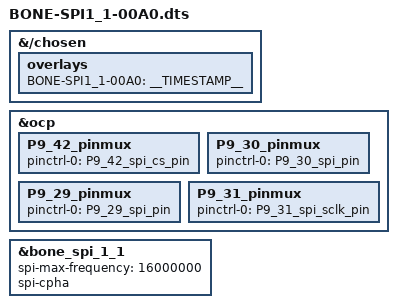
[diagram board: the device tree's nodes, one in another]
/*
 * Copyright (C) 2020 Deepak Khatri <deepaklorkhatri7@gmail.com>
 *
 * Virtual cape for /dev/bone/spi/1.1
 *
 * This program is free software; you can redistribute it and/or modify
 * it under the terms of the GNU General Public License version 2 as
 * published by the Free Software Foundation.
 */
 
/dts-v1/;
/plugin/;

/*
* Helper to show loaded overlays under: /proc/device-tree/chosen/overlays/
*/
&{/chosen} {
    overlays {
        BONE-SPI1_1-00A0 = __TIMESTAMP__;
    };
};

/*
* Free up the pins used by the cape from the pinmux helpers.
*/
&ocp {
	P9_42_pinmux { pinctrl-0 = <&P9_42_spi_cs_pin>; }; /* CS */
    P9_30_pinmux { pinctrl-0 = <&P9_30_spi_pin>; }; /* MOSI */
    P9_29_pinmux { pinctrl-0 = <&P9_29_spi_pin>; };	/* MISO */
    P9_31_pinmux { pinctrl-0 = <&P9_31_spi_sclk_pin>; }; /* CLK */
};

&bone_spi_1_1 {
    // See these files for the definition
    // https://github.com/beagleboard/BeagleBoard-DeviceTrees/src/arm/bbai-bone-buses.dtsi
    // https://github.com/beagleboard/BeagleBoard-DeviceTrees/src/arm/bbb-bone-buses.dtsi
    status = "okay";
	spi-max-frequency = <16000000>;
	spi-cpha;
};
